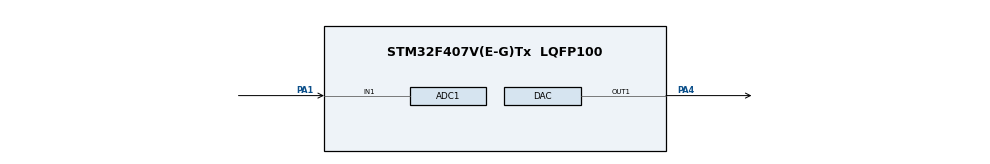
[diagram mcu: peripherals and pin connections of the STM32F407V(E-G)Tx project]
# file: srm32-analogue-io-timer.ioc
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ADC1.Channel-0\#ChannelRegularConversion=ADC_CHANNEL_1
ADC1.ContinuousConvMode=ENABLE
ADC1.NbrOfConversionFlag=1
ADC1.Rank-0\#ChannelRegularConversion=1
ADC1.SamplingTime-0\#ChannelRegularConversion=ADC_SAMPLETIME_3CYCLES
ADC1.master=1
DAC.DAC_Trigger=DAC_TRIGGER_T2_TRGO
Mcu.Family=STM32F4
Mcu.Name=STM32F407V(E-G)Tx
Mcu.Package=LQFP100
NVIC.PriorityGroup=NVIC_PRIORITYGROUP_0
PA1.Signal=ADCx_IN1
PA4.Signal=COMP_DAC1_group
PH0-OSC_IN.Mode=HSE-External-Oscillator
PH0-OSC_IN.Signal=RCC_OSC_IN
PH1-OSC_OUT.Mode=HSE-External-Oscillator
PH1-OSC_OUT.Signal=RCC_OSC_OUT
ProjectManager.TargetToolchain=TrueSTUDIO 4.3.1
RCC.APB1CLKDivider=RCC_HCLK_DIV4
RCC.APB2CLKDivider=RCC_HCLK_DIV8
RCC.HSE_VALUE=8000000
RCC.HSI_VALUE=16000000
RCC.LSE_VALUE=32768
RCC.PLLM=8
RCC.PLLN=336
RCC.PLLSource=RCC_PLLSOURCE_HSE
RCC.SYSCLKSource=RCC_SYSCLKSOURCE_PLLCLK
SH.ADCx_IN1.0=ADC1_IN1,IN1
SH.COMP_DAC1_group.0=DAC_OUT1,DAC_OUT1
TIM2.CounterMode=TIM_COUNTERMODE_DOWN
TIM2.Period=875
TIM2.Prescaler=1
VP_TIM2_VS_ClockSourceINT.Mode=Internal

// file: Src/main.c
/**
  ******************************************************************************
  * File Name          : main.c
  * Date               : 15/07/2014 15:40:47
  * Description        : Main program body
  ******************************************************************************
  */
#define INT16_TO_UINT12(x) ((uint32_t)(x + 2048))
#define UINT12_TO_INT16(x) ((int16_t)x - 2048)
#define DELAY_LENGTH_S 1
#define SAMPLING_RATE 48000
#define DELAY_LENGTH_SAMPS (DELAY_LENGTH_S * SAMPLING_RATE)

#include <stdlib.h>
#include <string.h>
#include "stm32f4xx_hal.h"

ADC_HandleTypeDef hadc1;

DAC_HandleTypeDef hdac;

TIM_HandleTypeDef htim2;

/* USER CODE BEGIN 0 */

int16_t *delayLine;

/* extern void HAL_TIM_TriggerCallback(TIM_HandleTypeDef *htim); */

/* USER CODE END 0 */

void SystemClock_Config(void);
static void MX_GPIO_Init(void);
static void MX_ADC1_Init(void);
static void MX_DAC_Init(void);
static void MX_TIM2_Init(void);

int main(void)
{

  /* USER CODE BEGIN 1 */

    delayLine = (int16_t*)malloc(sizeof(int16_t) *
            DELAY_LENGTH_SAMPS);
    memset(delayLine,0,sizeof(int16_t) * DELAY_LENGTH_SAMPS);

  /* USER CODE END 1 */

  /* MCU Configuration----------------------------------------------------------*/

  /* Reset of all peripherals, Initializes the Flash interface and the Systick. */
  HAL_Init();

  /* Configure the system clock */
  SystemClock_Config();

  /* System interrupt init*/
  /* Sets the priority grouping field */
  HAL_NVIC_SetPriorityGrouping(NVIC_PRIORITYGROUP_0);
  HAL_NVIC_SetPriority(SysTick_IRQn, 0, 0);

  /* Initialize all configured peripherals */
  MX_GPIO_Init();
  MX_ADC1_Init();
  MX_DAC_Init();
  MX_TIM2_Init();

  /* USER CODE BEGIN 2 */
  HAL_ADC_Start(&hadc1);
  HAL_DAC_Start(&hdac, DAC_CHANNEL_1);

  /* USER CODE END 2 */

  while (1)
  {
  }

}

/** System Clock Configuration
*/
void SystemClock_Config(void)
{

  RCC_ClkInitTypeDef RCC_ClkInitStruct;
  RCC_OscInitTypeDef RCC_OscInitStruct;

  __PWR_CLK_ENABLE();

  __HAL_PWR_VOLTAGESCALING_CONFIG(PWR_REGULATOR_VOLTAGE_SCALE1);

  RCC_OscInitStruct.OscillatorType = RCC_OSCILLATORTYPE_HSE;
  RCC_OscInitStruct.HSEState = RCC_HSE_ON;
  RCC_OscInitStruct.PLL.PLLState = RCC_PLL_ON;
  RCC_OscInitStruct.PLL.PLLSource = RCC_PLLSOURCE_HSE;
  RCC_OscInitStruct.PLL.PLLM = 8;
  RCC_OscInitStruct.PLL.PLLN = 336;
  RCC_OscInitStruct.PLL.PLLP = RCC_PLLP_DIV2;
  RCC_OscInitStruct.PLL.PLLQ = 4;
  HAL_RCC_OscConfig(&RCC_OscInitStruct);

  RCC_ClkInitStruct.ClockType = RCC_CLOCKTYPE_SYSCLK|RCC_CLOCKTYPE_PCLK1
                              |RCC_CLOCKTYPE_PCLK2;
  RCC_ClkInitStruct.SYSCLKSource = RCC_SYSCLKSOURCE_PLLCLK;
  RCC_ClkInitStruct.AHBCLKDivider = RCC_SYSCLK_DIV1;
  RCC_ClkInitStruct.APB1CLKDivider = RCC_HCLK_DIV4;
  RCC_ClkInitStruct.APB2CLKDivider = RCC_HCLK_DIV8;
  HAL_RCC_ClockConfig(&RCC_ClkInitStruct, FLASH_LATENCY_5);

}

/* ADC1 init function */
void MX_ADC1_Init(void)
{

  ADC_ChannelConfTypeDef sConfig;

    /**Configure the global features of the ADC (Clock, Resolution, Data Alignment and number of conversion)
    */
  hadc1.Instance = ADC1;
  hadc1.Init.ClockPrescaler = ADC_CLOCKPRESCALER_PCLK_DIV2;
  hadc1.Init.Resolution = ADC_RESOLUTION12b;
  hadc1.Init.ScanConvMode = DISABLE;
  hadc1.Init.ContinuousConvMode = ENABLE;
  hadc1.Init.DiscontinuousConvMode = DISABLE;
  hadc1.Init.NbrOfDiscConversion = 1;
  hadc1.Init.ExternalTrigConvEdge = ADC_EXTERNALTRIGCONVEDGE_NONE;
  hadc1.Init.DataAlign = ADC_DATAALIGN_RIGHT;
  hadc1.Init.NbrOfConversion = 1;
  hadc1.Init.DMAContinuousRequests = DISABLE;
  hadc1.Init.EOCSelection = EOC_SEQ_CONV; // Set end of conversion after the sequence?
  HAL_ADC_Init(&hadc1);

    /**Configure for the selected ADC regular channel its corresponding rank in the sequencer and its sample time.
    */
  sConfig.Channel = ADC_CHANNEL_1;
  sConfig.Rank = 1;
  sConfig.SamplingTime = ADC_SAMPLETIME_3CYCLES;
  HAL_ADC_ConfigChannel(&hadc1, &sConfig);

}

/* DAC init function */
void MX_DAC_Init(void)
{

  DAC_ChannelConfTypeDef sConfig;

    /**DAC Initialization
    */
  hdac.Instance = DAC;
  HAL_DAC_Init(&hdac);

    /**DAC channel OUT1 config
    */
  sConfig.DAC_Trigger = DAC_TRIGGER_NONE;
  sConfig.DAC_OutputBuffer = DAC_OUTPUTBUFFER_ENABLE;
  HAL_DAC_ConfigChannel(&hdac, &sConfig, DAC_CHANNEL_1);

}

/* TIM2 init function */
void MX_TIM2_Init(void)
{

  TIM_ClockConfigTypeDef sClockSourceConfig;
  TIM_MasterConfigTypeDef sMasterConfig;

  htim2.Instance = TIM2;
  htim2.Init.Prescaler = 1;
  htim2.Init.CounterMode = TIM_COUNTERMODE_UP;
  htim2.Init.Period = 875;
  htim2.Init.ClockDivision = TIM_CLOCKDIVISION_DIV1;
  htim2.Init.RepetitionCounter = 0;
  HAL_TIM_Base_Init(&htim2);
  // Initialize interrupt triggering
//  HAL_NVIC_EnableIRQ(TIM2_IRQn);

  sClockSourceConfig.ClockSource = TIM_CLOCKSOURCE_INTERNAL;
  HAL_TIM_ConfigClockSource(&htim2, &sClockSourceConfig);

  sMasterConfig.MasterOutputTrigger = TIM_TRGO_UPDATE;
  sMasterConfig.MasterSlaveMode = TIM_MASTERSLAVEMODE_DISABLE;
  HAL_TIMEx_MasterConfigSynchronization(&htim2, &sMasterConfig);
  if (HAL_TIM_Base_Start_IT(&htim2) != HAL_OK) {
      while(1);
  }

}

/** Configure pins as
        * Analog
        * Input
        * Output
        * EVENT_OUT
        * EXTI
*/
void MX_GPIO_Init(void)
{

  /* GPIO Ports Clock Enable */
  __GPIOH_CLK_ENABLE();
  __GPIOA_CLK_ENABLE();

}

void HAL_TIM_PeriodElapsedCallback(TIM_HandleTypeDef *htim)
{
    static size_t daddr = 0;
    if ( daddr >= DELAY_LENGTH_SAMPS) { daddr = 0; }
    uint32_t value = HAL_ADC_GetValue(&hadc1);
    int16_t outval = delayLine[daddr];
    delayLine[daddr] = UINT12_TO_INT16(value)
        + (int16_t)((int32_t)outval * 9 / 10);
    daddr++;
    HAL_DAC_SetValue(&hdac, DAC_CHANNEL_1, DAC_ALIGN_12B_R, INT16_TO_UINT12(outval));
}

/************************ (C) COPYRIGHT STMicroelectronics *****END OF FILE****/
